# hercules_rti_spec_3.2.1 register map
Vendor: Texas Instruments
Peripheral module from a debugger description file (folder hercules).
Registers are 32-bit, read-write, reset 0x0 unless marked. A register's access mark holds for its fields unless they carry their own. Offsets are as the file gives them; lines under a group give offsets from that group; [hi:lo] are bit positions; {n}, {i} and the like mark numbered series; 'fields as' and 'values as' point back to an identical list; <NAME> marks a mode.

## Rti — Real Time Interrupt
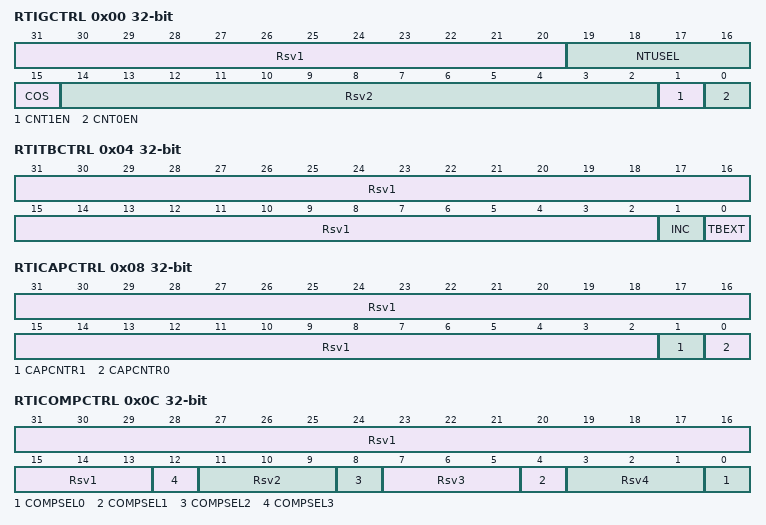
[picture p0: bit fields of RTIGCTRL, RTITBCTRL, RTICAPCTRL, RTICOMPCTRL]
0x00 RTIGCTRL access per field — RTI Global Control Register
  [31:20] Rsv1 ro — Reserved
  [19:16] NTUSEL rw — Select NTU Timebase: 0x0=NTU0, 0x5=NTU1, 0xA=NTU2, 0xF=NTU3, Others=Disabled
  [15] COS rw — 1 = Counters Run while CPU Is Halted in Debug Mode
  [14:2] Rsv2 ro — Reserved
  [1] CNT1EN rw — 1 = Counter Block 1 is Running
  [0] CNT0EN rw — 1 = Counter Block 0 is Running
0x04 RTITBCTRL access per field — RTI Timebase Control Register
  [31:2] Rsv1 ro — Reserved
  [1] INC rw — 1 = RTIFRC0 will be incremented on a failing external clock.
  [0] TBEXT rw — Select Clock for RTIFRC0, 0=RTIUC0, 1=NTU
0x08 RTICAPCTRL access per field — RTI Capture Control Register
  [31:2] Rsv1 ro — Reserved
  [1] CAPCNTR1 rw — Capture of RTIUC1/ RTIFRC1 is triggered by capture event 0=source 0, 1=source 1
  [0] CAPCNTR0 rw — Capture of RTIUC0/ RTIFRC0 is triggered by capture event 0=source 0, 1=source 1
0x0C RTICOMPCTRL access per field — RTI Compare Control Register
  [31:13] Rsv1 ro — Reserved
  [4n] COMPSEL{n} rw (n=0..3) — RTICOMP{n} Compared against 0=RTIFRC0, 1=RTIFRC1
  [11:9] Rsv2 ro — Reserved
  [7:5] Rsv3 ro — Reserved
  [3:1] Rsv4 ro — Reserved
0x10 RTIFRC0 — RTI Free Running Counter 0 Register
  [31:0] FRC0 — Free Running Counter 0
0x14 RTIUC0 — RTI Up Counter 0 Register
  [31:0] UC0 — Up Counter 0
0x18 RTICPUC0 — RTI Compare Up Counter 0 Register
  [31:0] CPUC0 — Compare up counter 0.
0x20 RTICAFRC0 ro — RTI Capture Free Running Counter 0 Register
  [31:0] CAFRC0 — Capture free running counter 0.
0x24 RTICAUC0 ro — RTI Capture Up Counter 0 Register
  [31:0] CAUC0 — Capture up counter 0.
0x30 RTIFRC1 — RTI Free Running Counter 1 Register
  [31:0] FRC1 — Free Running Counter 1
0x34 RTIUC1 — RTI Up Counter 1 Register
  [31:0] UC1 — Up Counter 1
0x38 RTICPUC1 — RTI Compare Up Counter 1 Register
  [31:0] CPUC1 — Compare up counter 1.
0x40 RTICAFRC1 ro — RTI Capture Free Running Counter 1 Register
  [31:0] CAFRC1 — Capture free running counter 1.
0x44 RTICAUC1 ro — RTI Capture Up Counter 1 Register
  [31:0] CAUC1 — Capture up counter 1.
{0x50+8i} RTICOMP{i} (i=0..3) — RTI Compare {i} Register
  [31:0] COMP{i} — Compare {i}.
{0x54+8i} RTIUDCP{i} (i=0..2) — RTI Update Compare {i} Register
  [31:0] UDCP{i} — Update Compare {i}.
0x6C RTIUDCP3 — RTI Update Compare 2 Register
  [31:0] UDCP3 — Update Compare 3.
0x70 RTITBLCOMP — RTI Timebase Low Compare Register
  [31:0] TBLCOMP — Timebase low compare value. Determines when edge detection circuit begins monitoring NTU, Compared against RTIUC0.
0x74 RTITBHCOMP — RTI Timebase High Compare Register
  [31:0] TBHCOMP — Timebase high compare value. Determines when edge detection circuit stops monitoring NTU, Compared against RTIUC0.
0x80 RTISETINTENA access per field — RTI Set Interrupt Register
  [31:19] Rsv1 ro — Reserved
  [18] SETOVL1INT rw — Set RTIFRC1 Overflow Interrupt Enable, W12S
  [17] SETOVL0INT rw — Set RTIFRC0 Overflow Interrupt Enable, W12S
  [16] SETTBINT rw — Set Timebase Interrupt Enable, W12S
  [15:12] Rsv2 ro — Reserved
  [n+8] SETDMA{n} rw (n=0..3) — Set Compare DMA Request {n} Enable, W12S
  [n+8] SETINT{n} rw (n=0..3) — Set Compare Interrupt Request {n} Enable, W12S
  [7:4] Rsv3 ro — Reserved
0x84 RTICLEARINTENA access per field — RTI Clear Interrupt Enable Register
  [31:19] Rsv1 ro — Reserved
  [18] CLEAROVL1INT rw — CLEAR RTIFRC1 Overflow Interrupt Enable, W12C
  [17] CLEAROVL0INT rw — CLEAR RTIFRC0 Overflow Interrupt Enable, W12C
  [16] CLEARTBINT rw — CLEAR Timebase Interrupt Enable, W12C
  [15:12] Rsv2 ro — Reserved
  [n+8] CLEARDMA{n} rw (n=0..3) — CLEAR Compare DMA Request {n} Enable, W12C
  [n+8] CLEARINT{n} rw (n=0..3) — CLEAR Compare Interrupt Request {n} Enable, W12C
  [7:4] Rsv3 ro — Reserved
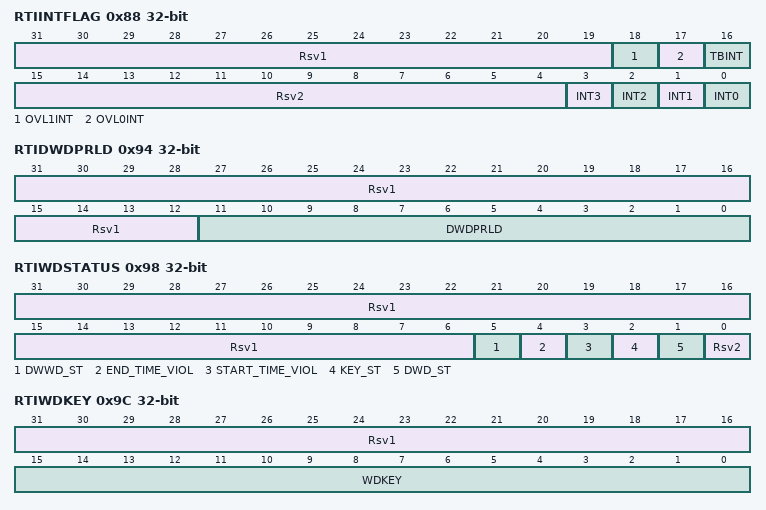
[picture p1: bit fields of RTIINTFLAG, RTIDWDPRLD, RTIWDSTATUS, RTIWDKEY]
0x88 RTIINTFLAG access per field — RTI Interrupt Flag Register
  [31:19] Rsv1 ro — Reserved
  [18] OVL1INT rw — RTIFRC1 Overflow Interrupt Flag, W12C
  [17] OVL0INT rw — RTIFRC0 Overflow Interrupt Flag, W12C
  [16] TBINT rw — Timebase Interrupt Flag, W12C
  [15:4] Rsv2 ro — Reserved
  [n] INT{n} rw (n=0..3) — Compare Interrupt Flag {n}, W12C
0x90 RTIDWDCTRL — Digital Watchdog Control Register
  [31:0] DWDCTRL — 0x5312ACED = Disabled, 0xA98559DA = Enabled, Others - Unchanged.
0x94 RTIDWDPRLD access per field — Digital Watchdog Preload Register
  [31:12] Rsv1 ro — Reserved
  [11:0] DWDPRLD rw — Preload: texp = (DWDPRLD+1) x 2 13 / RTICLK1
0x98 RTIWDSTATUS access per field — Watchdog Status Register
  [31:6] Rsv1 ro — Reserved
  [5] DWWD_ST rw — Windowed Watchdog Status 1=Time Window Violation, W12C
  [4] END_TIME_VIOL rw — Windowed Watchdog Status 1=End Time Window Violation, W12C
  [3] START_TIME_VIOL rw — Windowed Watchdog Status 1=Starr Time Window Violation, W12C
  [2] KEY_ST rw — Windowed Watchdog Status 1=Wrong Key Violation, W12C, W12C
  [1] DWD_ST rw — Same as END_TIME_VIOL, W12C
  [0] Rsv2 rw — Reserved
0x9C RTIWDKEY access per field — RTI Watchdog Key Register
  [31:16] Rsv1 ro — Reserved
  [15:0] WDKEY rw — Key Sequence: Write 0xE51A followed by 0xA35C to Reset DWD
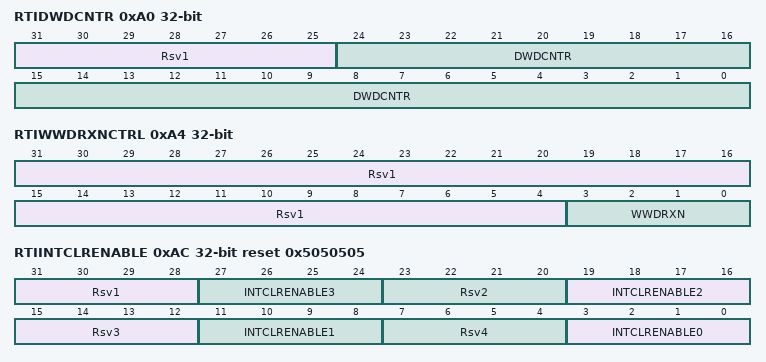
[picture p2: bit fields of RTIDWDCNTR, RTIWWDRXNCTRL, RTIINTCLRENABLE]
0xA0 RTIDWDCNTR ro — RTI Digital Watchdog Down Counter
  [31:25] Rsv1 — Reserved
  [24:0] DWDCNTR — DWD down counter
0xA4 RTIWWDRXNCTRL ro — Digital Windowed Watchdog Reaction Control
  [31:4] Rsv1 — Reserved
  [3:0] WWDRXN — DWD reaction: 0xA -> NMI, 0x5,others->Reset
0xA8 RTIWWDSIZECTRL — Digital Windowed Watchdog Window Size Control
  [31:0] WWDSIZE — DWWD Window Size 0x5=100%, 0x50=50%, 0x500=25% 0x5000=12.5%, 0x50000=6.25% Others =3.125%
0xAC RTIINTCLRENABLE access per field reset 0x5050505 — RTI Compare Interrupt Clear Enable Register
  [39-8n:36-8n] Rsv{n} ro (n=1..4) — Reserved
  [8n+3:8n] INTCLRENABLE{n} rw (n=0..3) — 0x5 = Auto-Clear for RTICOMP{n} Interrupt Disabled, Others=Enabled
{0xB0+4i} RTICOMP{i}CLR (i=0..3) — RTI Compare {i} Clear Register
  [31:0] CMP{i}CLR — Compare {i} clear. Interrupt Flag Cleared on Compare Match

## Notices in the file
(c) Texas Instruments 2003-2014, All rights reserved.
